# f28e12x_dev_cfg_regs register map
Vendor: Texas Instruments
Peripheral module from a debugger description file (folder C2000).
Address unit: 16 bits
Registers are 32-bit, read-write, no defined reset value unless marked. A register's access mark holds for its fields unless they carry their own. Offsets are as the file gives them; lines under a group give offsets from that group; [hi:lo] are bit positions; {n}, {i} and the like mark numbered series; 'fields as' and 'values as' point back to an identical list; <NAME> marks a mode.

## DEV_CFG_REGS — DEV CFG Registers
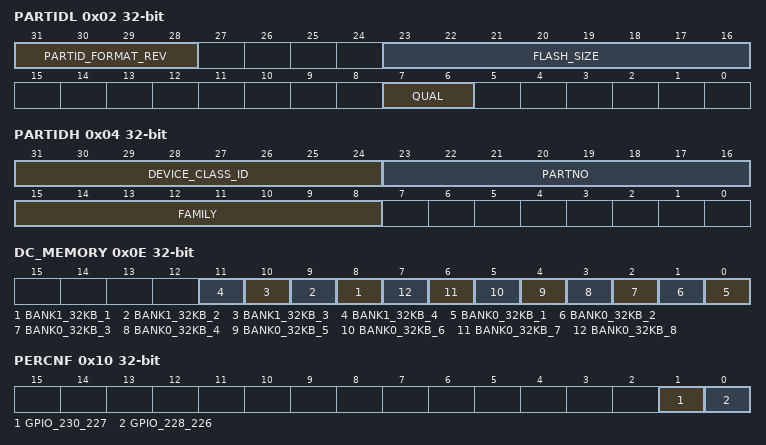
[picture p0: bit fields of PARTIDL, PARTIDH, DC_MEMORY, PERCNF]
0x02 PARTIDL — Lower 32-bit of Device PART Identification Number
  [31:28] PARTID_FORMAT_REV
  [23:16] FLASH_SIZE
  [7:6] QUAL — Qualification Status
0x04 PARTIDH access per field — Upper 32-bit of Device PART Identification Number
  [31:24] DEVICE_CLASS_ID ro
  [23:16] PARTNO rw — Device part number
  [15:8] FAMILY rw — Device family
0x06 REVID — Device Revision Number
  [15:0] REVID — Device Revision ID. This is specific to the Device
0x0E DC_MEMORY — Device Capability: Memory Blocks Customization
  [n+7] BANK1_32KB_{n} (n=1..4) — BANK1_32KB_{n} present
  [n-1] BANK0_32KB_{n} (n=1..8) — BANK0_32KB_{n} present
0x10 PERCNF — Peripheral Configuration register - GPIO
  [1] GPIO_230_227 — GPIO227, GPIO230 Double bond protection configuration
  [0] GPIO_228_226 — GPIO226, GPIO228 Double bond protection configuration
0x12 TRIMERRSTS — TRIM Error Status register
  [15:0] LERR — TRIM Load error status
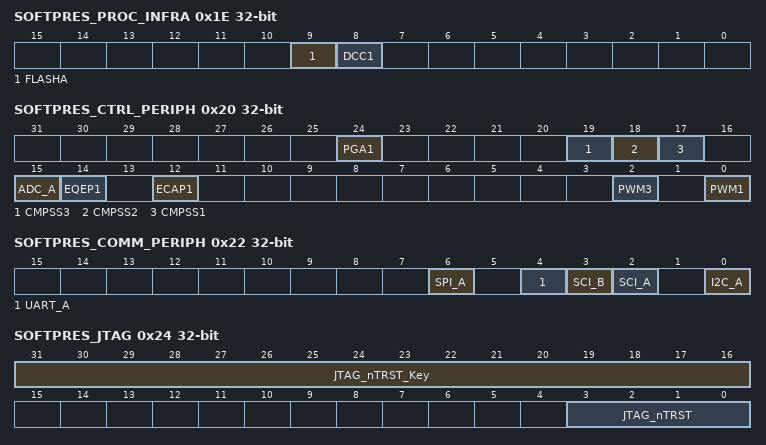
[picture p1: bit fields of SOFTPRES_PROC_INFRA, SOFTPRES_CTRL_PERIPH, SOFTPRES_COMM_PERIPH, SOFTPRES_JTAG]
0x1E SOFTPRES_PROC_INFRA — Processing and Infra Blocks Software Reset register
  [9] FLASHA — FLASHA soft reset
  [8] DCC1 — DCC1 soft reset
0x20 SOFTPRES_CTRL_PERIPH — Control Peripherals Software Reset register
  [24] PGA1 — PGA1 soft reset
  [19] CMPSS3 — CMPSS3 soft reset
  [18] CMPSS2 — CMPSS2 soft reset
  [17] CMPSS1 — CMPSS1 soft reset
  [15] ADC_A — ADC_A soft reset
  [14] EQEP1 — EQEP1 soft reset
  [12] ECAP1 — ECAP1 soft reset
  [2] PWM3 — PWM3 soft reset
  [0] PWM1 — PWM1 soft reset
0x22 SOFTPRES_COMM_PERIPH — Communication Peripherals Software Reset register
  [6] SPI_A — SPI_A soft reset
  [4] UART_A — UART_A soft reset
  [3] SCI_B — SCI_B soft reset
  [2] SCI_A — SCI_A soft reset
  [0] I2C_A — I2C_A soft reset
0x24 SOFTPRES_JTAG — JTAG Software Reset register
  [31:16] JTAG_nTRST_Key
  [3:0] JTAG_nTRST — Multi Bit JTAG nTRST
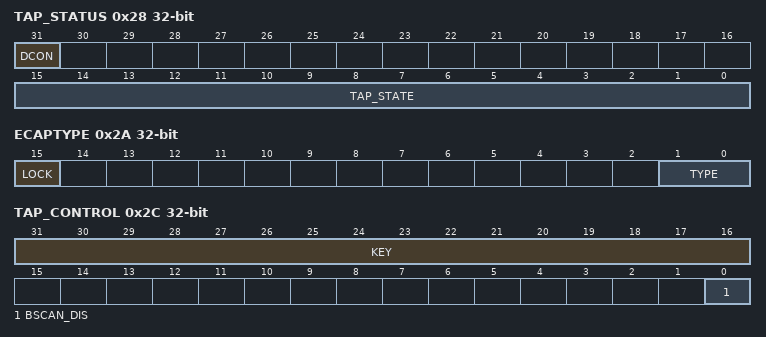
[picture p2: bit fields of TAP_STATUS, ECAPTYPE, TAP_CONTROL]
0x28 TAP_STATUS ro — Status of JTAG State machine and Debugger Connect
  [31] DCON — Debugger Connect Indication
  [15:0] TAP_STATE — Present TAP State
0x2A ECAPTYPE — Configures ECAP Type for the device
  [15] LOCK — Lock bit for the register
  [1:0] TYPE — Configure ECAP type
0x2C TAP_CONTROL — Disable TAP control
  [31:16] KEY — Key value to enable write
  [0] BSCAN_DIS — Disable BSCAN TAP control
